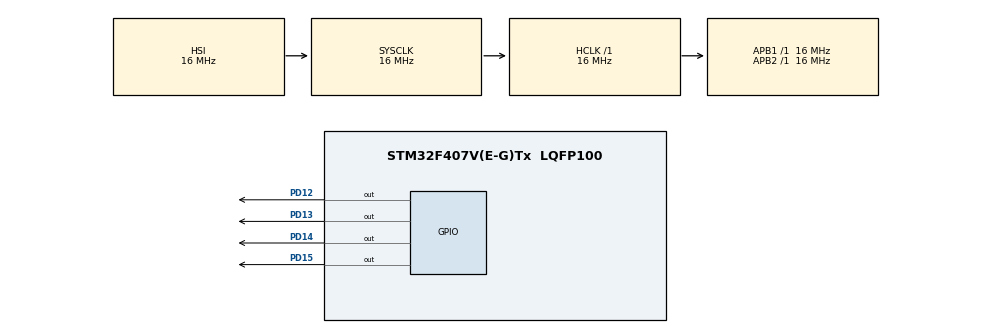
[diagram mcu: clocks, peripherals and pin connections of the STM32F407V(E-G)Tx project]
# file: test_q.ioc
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Mcu.Family=STM32F4
Mcu.Name=STM32F407V(E-G)Tx
Mcu.Package=LQFP100
NVIC.PriorityGroup=NVIC_PRIORITYGROUP_4
PD12.Signal=GPIO_Output
PD13.Signal=GPIO_Output
PD14.Signal=GPIO_Output
PD15.Signal=GPIO_Output
ProjectManager.HeapSize=0x200
ProjectManager.StackSize=0x400
ProjectManager.TargetToolchain=STM32CubeIDE
RCC.AHBFreq_Value=16000000
RCC.APB1Freq_Value=16000000
RCC.APB2Freq_Value=16000000
RCC.CortexFreq_Value=16000000
RCC.HSE_VALUE=25000000
RCC.HSI_VALUE=16000000
RCC.LSE_VALUE=32768
RCC.SYSCLKFreq_VALUE=16000000
RCC.VCOOutputFreq_Value=192000000
board=custom

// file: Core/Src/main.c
/* USER CODE BEGIN Header */
/**
 ******************************************************************************
 * @file           : main.c
 * @brief          : Main program body
 ******************************************************************************
 * @attention
 *
 * Copyright (c) 2024 STMicroelectronics.
 * All rights reserved.
 *
 * This software is licensed under terms that can be found in the LICENSE file
 * in the root directory of this software component.
 * If no LICENSE file comes with this software, it is provided AS-IS.
 *
 ******************************************************************************
 */
/* USER CODE END Header */
#include "main.h"
#include <stdio.h>

void SystemClock_Config(void);
static void MX_GPIO_Init(void);

#define DEFAULT_DELAY 100 // default delay constant in milliseconds
delay_t delay_a;
void delayInit( delay_t * delay, tick_t duration );
bool_t delayRead( delay_t * delay );
void delayWrite( delay_t * delay, tick_t duration );

/**
 * @brief Inits a delay with a specified duration.
 * Function that initiates a delay.
 * @param delay Pointer to a defined delay struct.
 * @param duration in milliseconds.
 * @note if duration is 0 or a negative number, it defaults to DEFAULT_DELAY.
 */
void delayInit(delay_t *delay, tick_t duration){
	if (duration <= 0){
		duration = DEFAULT_DELAY;
	}
	delay->duration = duration;
	delay->running = false;
	delay->startTime = 0;

}

/**
 * @brief Checks if an specific delay has elapsed.
 * Function that checks the current status of a delay and updates its values.
 * @param delay Pointer to a defined delay struct.
 * @retval bool indicating running state.
 */
bool_t delayRead(delay_t *delay){

	tick_t currentTime = HAL_GetTick();
	bool isRunning = delay->running;

	if (isRunning && (currentTime - delay->startTime >= delay->duration)){
		delay->running = false;
		return true;
	}

	if (!isRunning) {
		delay->running = true;
		delay->startTime = currentTime;

	}
	return false;
}

/**
 * @brief Writes/updates the duration on a defined delay.
 * Function that writes a duration value on a delay.
 * @param delay Pointer to a defined delay struct.
 * @param duration new duration value in milliseconds.
 * @note if duration is 0 or a negative number, it defaults to DEFAULT_DELAY.
 */
void delayWrite(delay_t *delay,tick_t duration){
	if (duration <= 0){
		duration = DEFAULT_DELAY;
	}
	delay->duration = duration;
}
int main(void)
{

	/* MCU Configuration--------------------------------------------------------*/

	/* Reset of all peripherals, Initializes the Flash interface and the Systick. */
	HAL_Init();

	/* Configure the system clock */
	SystemClock_Config();

	/* Initialize all configured peripherals */
	MX_GPIO_Init();

	/* Infinite loop */
	/* USER CODE BEGIN WHILE */
	delayInit(&delay_a, 500);

	while (1)
	{

		if (delayRead(&delay_a)){
			HAL_GPIO_TogglePin(GPIOD, GPIO_PIN_12);

		}
		/* USER CODE END WHILE */

	}
}

void SystemClock_Config(void)
{
	RCC_OscInitTypeDef RCC_OscInitStruct = {0};
	RCC_ClkInitTypeDef RCC_ClkInitStruct = {0};

	/** Configure the main internal regulator output voltage
	 */
	__HAL_RCC_PWR_CLK_ENABLE();
	__HAL_PWR_VOLTAGESCALING_CONFIG(PWR_REGULATOR_VOLTAGE_SCALE1);

	/** Initializes the RCC Oscillators according to the specified parameters
	 * in the RCC_OscInitTypeDef structure.
	 */
	RCC_OscInitStruct.OscillatorType = RCC_OSCILLATORTYPE_HSI;
	RCC_OscInitStruct.HSIState = RCC_HSI_ON;
	RCC_OscInitStruct.HSICalibrationValue = RCC_HSICALIBRATION_DEFAULT;
	RCC_OscInitStruct.PLL.PLLState = RCC_PLL_NONE;
	if (HAL_RCC_OscConfig(&RCC_OscInitStruct) != HAL_OK)
	{
		Error_Handler();
	}

	/** Initializes the CPU, AHB and APB buses clocks
	 */
	RCC_ClkInitStruct.ClockType = RCC_CLOCKTYPE_HCLK|RCC_CLOCKTYPE_SYSCLK
			|RCC_CLOCKTYPE_PCLK1|RCC_CLOCKTYPE_PCLK2;
	RCC_ClkInitStruct.SYSCLKSource = RCC_SYSCLKSOURCE_HSI;
	RCC_ClkInitStruct.AHBCLKDivider = RCC_SYSCLK_DIV1;
	RCC_ClkInitStruct.APB1CLKDivider = RCC_HCLK_DIV1;
	RCC_ClkInitStruct.APB2CLKDivider = RCC_HCLK_DIV1;

	if (HAL_RCC_ClockConfig(&RCC_ClkInitStruct, FLASH_LATENCY_0) != HAL_OK)
	{
		Error_Handler();
	}
}

static void MX_GPIO_Init(void)
{
	GPIO_InitTypeDef GPIO_InitStruct = {0};

	/* GPIO Ports Clock Enable */
	__HAL_RCC_GPIOD_CLK_ENABLE();

	/*Configure GPIO pin Output Level */
	HAL_GPIO_WritePin(GPIOD, GPIO_PIN_12|GPIO_PIN_13|GPIO_PIN_14|GPIO_PIN_15, GPIO_PIN_RESET);

	/*Configure GPIO pins : PD12 PD13 PD14 PD15 */
	GPIO_InitStruct.Pin = GPIO_PIN_12|GPIO_PIN_13|GPIO_PIN_14|GPIO_PIN_15;
	GPIO_InitStruct.Mode = GPIO_MODE_OUTPUT_PP;
	GPIO_InitStruct.Pull = GPIO_NOPULL;
	GPIO_InitStruct.Speed = GPIO_SPEED_FREQ_LOW;
	HAL_GPIO_Init(GPIOD, &GPIO_InitStruct);

}

void Error_Handler(void)
{
	__disable_irq();
	while (1)
	{
	}
}
